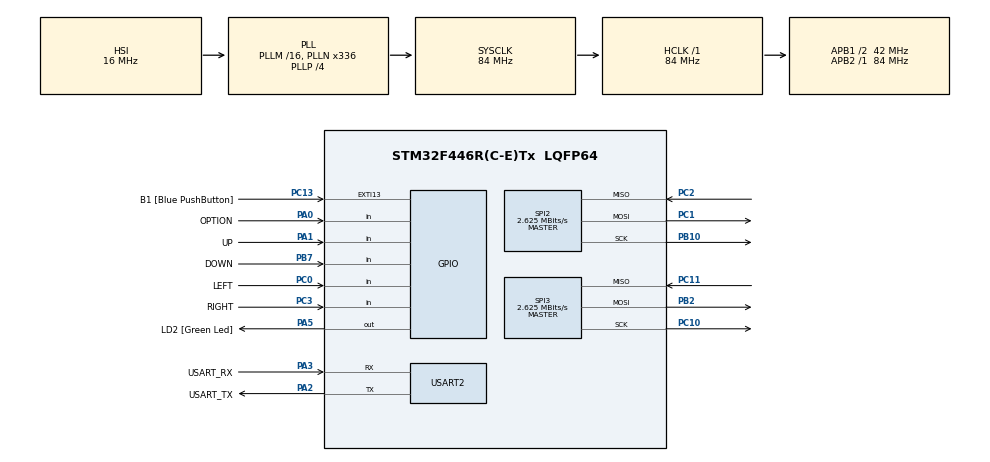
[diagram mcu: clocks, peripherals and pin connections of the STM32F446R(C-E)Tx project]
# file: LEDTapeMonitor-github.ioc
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Dma.Request0=SPI3_TX
Dma.Request1=SPI2_TX
Dma.SPI2_TX.1.Direction=DMA_MEMORY_TO_PERIPH
Dma.SPI2_TX.1.FIFOMode=DMA_FIFOMODE_DISABLE
Dma.SPI2_TX.1.Instance=DMA1_Stream4
Dma.SPI2_TX.1.MemDataAlignment=DMA_MDATAALIGN_BYTE
Dma.SPI2_TX.1.MemInc=DMA_MINC_ENABLE
Dma.SPI2_TX.1.Mode=DMA_NORMAL
Dma.SPI2_TX.1.PeriphDataAlignment=DMA_PDATAALIGN_BYTE
Dma.SPI2_TX.1.PeriphInc=DMA_PINC_DISABLE
Dma.SPI2_TX.1.Priority=DMA_PRIORITY_LOW
Dma.SPI3_TX.0.Direction=DMA_MEMORY_TO_PERIPH
Dma.SPI3_TX.0.FIFOMode=DMA_FIFOMODE_DISABLE
Dma.SPI3_TX.0.Instance=DMA1_Stream5
Dma.SPI3_TX.0.MemDataAlignment=DMA_MDATAALIGN_BYTE
Dma.SPI3_TX.0.MemInc=DMA_MINC_ENABLE
Dma.SPI3_TX.0.Mode=DMA_NORMAL
Dma.SPI3_TX.0.PeriphDataAlignment=DMA_PDATAALIGN_BYTE
Dma.SPI3_TX.0.PeriphInc=DMA_PINC_DISABLE
Dma.SPI3_TX.0.Priority=DMA_PRIORITY_LOW
Mcu.Family=STM32F4
Mcu.Name=STM32F446R(C-E)Tx
Mcu.Package=LQFP64
NVIC.DMA1_Stream4_IRQn=true\:0\:0\:false\:false\:true\:false\:true
NVIC.DMA1_Stream5_IRQn=true\:0\:0\:false\:false\:true\:false\:true
NVIC.PriorityGroup=NVIC_PRIORITYGROUP_0
PA0-WKUP.GPIO_Label=OPTION
PA0-WKUP.GPIO_PuPd=GPIO_PULLDOWN
PA0-WKUP.Signal=GPIO_Input
PA1.GPIO_Label=UP
PA1.GPIO_PuPd=GPIO_NOPULL
PA1.Signal=GPIO_Input
PA13.GPIO_Label=TMS
PA13.Mode=Serial_Wire
PA13.Signal=SYS_JTMS-SWDIO
PA14.GPIO_Label=TCK
PA14.Mode=Serial_Wire
PA14.Signal=SYS_JTCK-SWCLK
PA2.GPIO_Label=USART_TX
PA2.Mode=Asynchronous
PA2.Signal=USART2_TX
PA3.GPIO_Label=USART_RX
PA3.Mode=Asynchronous
PA3.Signal=USART2_RX
PA5.GPIO_Label=LD2 [Green Led]
PA5.Signal=GPIO_Output
PB10.Mode=Full_Duplex_Master
PB10.Signal=SPI2_SCK
PB2.Mode=Full_Duplex_Master
PB2.Signal=SPI3_MOSI
PB3.GPIO_Label=SWO
PB3.Signal=SYS_JTDO-SWO
PB7.GPIO_Label=DOWN
PB7.GPIO_PuPd=GPIO_NOPULL
PB7.Signal=GPIO_Input
PC0.GPIO_Label=LEFT
PC0.GPIO_PuPd=GPIO_NOPULL
PC0.Signal=GPIO_Input
PC1.GPIO_PuPd=GPIO_PULLDOWN
PC1.Mode=Full_Duplex_Master
PC1.Signal=SPI2_MOSI
PC10.Mode=Full_Duplex_Master
PC10.Signal=SPI3_SCK
PC11.Mode=Full_Duplex_Master
PC11.Signal=SPI3_MISO
PC13.GPIO_Label=B1 [Blue PushButton]
PC13.GPIO_ModeDefaultEXTI=GPIO_MODE_IT_FALLING
PC13.Signal=GPXTI13
PC14-OSC32_IN.Mode=LSE-External-Oscillator
PC14-OSC32_IN.Signal=RCC_OSC32_IN
PC15-OSC32_OUT.Mode=LSE-External-Oscillator
PC15-OSC32_OUT.Signal=RCC_OSC32_OUT
PC2.Mode=Full_Duplex_Master
PC2.Signal=SPI2_MISO
PC3.GPIO_Label=RIGHT
PC3.GPIO_PuPd=GPIO_NOPULL
PC3.Signal=GPIO_Input
PH0-OSC_IN.Mode=HSE-External-Oscillator
PH0-OSC_IN.Signal=RCC_OSC_IN
PH1-OSC_OUT.Mode=HSE-External-Oscillator
PH1-OSC_OUT.Signal=RCC_OSC_OUT
ProjectManager.HeapSize=0x200
ProjectManager.StackSize=0x400
ProjectManager.TargetToolchain=STM32CubeIDE
RCC.48MHZClocksFreq_Value=84000000
RCC.AHBFreq_Value=84000000
RCC.APB1CLKDivider=RCC_HCLK_DIV2
RCC.APB1Freq_Value=42000000
RCC.APB1TimFreq_Value=84000000
RCC.APB2Freq_Value=84000000
RCC.APB2TimFreq_Value=84000000
RCC.CortexFreq_Value=84000000
RCC.FLatency-AdvancedSettings=FLASH_LATENCY_2
RCC.HCLKFreq_Value=84000000
RCC.HSE_VALUE=8000000
RCC.HSI_VALUE=16000000
RCC.PLLN=336
RCC.PLLP=RCC_PLLP_DIV4
RCC.SYSCLKFreq_VALUE=84000000
RCC.SYSCLKSource=RCC_SYSCLKSOURCE_PLLCLK
RCC.USBFreq_Value=168000000
RCC.VCOOutputFreq_Value=336000000
SPI2.BaudRatePrescaler=SPI_BAUDRATEPRESCALER_16
SPI2.CLKPhase=SPI_PHASE_2EDGE
SPI2.CalculateBaudRate=2.625 MBits/s
SPI2.Direction=SPI_DIRECTION_2LINES
SPI2.Mode=SPI_MODE_MASTER
SPI2.VirtualType=VM_MASTER
SPI3.BaudRatePrescaler=SPI_BAUDRATEPRESCALER_16
SPI3.CLKPhase=SPI_PHASE_2EDGE
SPI3.CalculateBaudRate=2.625 MBits/s
SPI3.Direction=SPI_DIRECTION_2LINES
SPI3.Mode=SPI_MODE_MASTER
SPI3.VirtualType=VM_MASTER
TIM6.Period=999
TIM6.Prescaler=8399
USART2.VirtualMode=VM_ASYNC
VP_TIM6_VS_ClockSourceINT.Mode=Enable_Timer
board=NUCLEO-F446RE

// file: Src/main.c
/* USER CODE BEGIN Header */
/**
  ******************************************************************************
  * @file           : main.c
  * @brief          : Main program body
  ******************************************************************************
  * @attention
  *
  * <h2><center>&copy; Copyright (c) 2019 STMicroelectronics.
  * All rights reserved.</center></h2>
  *
  * This software component is licensed by ST under BSD 3-Clause license,
  * the "License"; You may not use this file except in compliance with the
  * License. You may obtain a copy of the License at:
  *                        opensource.org/licenses/BSD-3-Clause
  *
  ******************************************************************************
  */
/* USER CODE END Header */

#include "main.h"

/* USER CODE BEGIN Includes */
uint8_t monitor[20][10] = {};//6bit目から2bitずつR G B
uint8_t spi_data[2400] = {};
#include "controlLed.h"
#include "tetris.h"
/* USER CODE END Includes */

SPI_HandleTypeDef hspi2;
SPI_HandleTypeDef hspi3;
DMA_HandleTypeDef hdma_spi2_tx;
DMA_HandleTypeDef hdma_spi3_tx;

TIM_HandleTypeDef htim6;

UART_HandleTypeDef huart2;

void SystemClock_Config(void);
static void MX_GPIO_Init(void);
static void MX_DMA_Init(void);
static void MX_SPI3_Init(void);
static void MX_USART2_UART_Init(void);
static void MX_TIM6_Init(void);
static void MX_SPI2_Init(void);

int main(void)
{

  /* MCU Configuration--------------------------------------------------------*/

  /* Reset of all peripherals, Initializes the Flash interface and the Systick. */
  HAL_Init();

  /* Configure the system clock */
  SystemClock_Config();

  /* Initialize all configured peripherals */
  MX_GPIO_Init();
  MX_DMA_Init();
  MX_SPI3_Init();
  MX_USART2_UART_Init();
  MX_TIM6_Init();
  MX_SPI2_Init();

  /* Infinite loop */
  while (1)
  {

    /* USER CODE BEGIN 3 */

	  playTetris();
	  writeLED();
	  HAL_SPI_Transmit_DMA(&hspi2, spi_data, 2400);
	  //HAL_Delay(1000);
	  //HAL_GPIO_WritePin(GPIOC,GPIO_PIN_1,0);
	  //HAL_Delay(1000);
	 // HAL_GPIO_WritePin(GPIOC,GPIO_PIN_1,1);

  }
  /* USER CODE END 3 */
}

void SystemClock_Config(void)
{
  RCC_OscInitTypeDef RCC_OscInitStruct = {0};
  RCC_ClkInitTypeDef RCC_ClkInitStruct = {0};

  /** Configure the main internal regulator output voltage
  */
  __HAL_RCC_PWR_CLK_ENABLE();
  __HAL_PWR_VOLTAGESCALING_CONFIG(PWR_REGULATOR_VOLTAGE_SCALE3);
  /** Initializes the CPU, AHB and APB busses clocks
  */
  RCC_OscInitStruct.OscillatorType = RCC_OSCILLATORTYPE_HSI;
  RCC_OscInitStruct.HSIState = RCC_HSI_ON;
  RCC_OscInitStruct.HSICalibrationValue = RCC_HSICALIBRATION_DEFAULT;
  RCC_OscInitStruct.PLL.PLLState = RCC_PLL_ON;
  RCC_OscInitStruct.PLL.PLLSource = RCC_PLLSOURCE_HSI;
  RCC_OscInitStruct.PLL.PLLM = 16;
  RCC_OscInitStruct.PLL.PLLN = 336;
  RCC_OscInitStruct.PLL.PLLP = RCC_PLLP_DIV4;
  RCC_OscInitStruct.PLL.PLLQ = 2;
  RCC_OscInitStruct.PLL.PLLR = 2;
  if (HAL_RCC_OscConfig(&RCC_OscInitStruct) != HAL_OK)
  {
    Error_Handler();
  }
  /** Initializes the CPU, AHB and APB busses clocks
  */
  RCC_ClkInitStruct.ClockType = RCC_CLOCKTYPE_HCLK|RCC_CLOCKTYPE_SYSCLK
                              |RCC_CLOCKTYPE_PCLK1|RCC_CLOCKTYPE_PCLK2;
  RCC_ClkInitStruct.SYSCLKSource = RCC_SYSCLKSOURCE_PLLCLK;
  RCC_ClkInitStruct.AHBCLKDivider = RCC_SYSCLK_DIV1;
  RCC_ClkInitStruct.APB1CLKDivider = RCC_HCLK_DIV2;
  RCC_ClkInitStruct.APB2CLKDivider = RCC_HCLK_DIV1;

  if (HAL_RCC_ClockConfig(&RCC_ClkInitStruct, FLASH_LATENCY_2) != HAL_OK)
  {
    Error_Handler();
  }
}

static void MX_SPI2_Init(void)
{

  /* SPI2 parameter configuration*/
  hspi2.Instance = SPI2;
  hspi2.Init.Mode = SPI_MODE_MASTER;
  hspi2.Init.Direction = SPI_DIRECTION_2LINES;
  hspi2.Init.DataSize = SPI_DATASIZE_8BIT;
  hspi2.Init.CLKPolarity = SPI_POLARITY_LOW;
  hspi2.Init.CLKPhase = SPI_PHASE_2EDGE;
  hspi2.Init.NSS = SPI_NSS_SOFT;
  hspi2.Init.BaudRatePrescaler = SPI_BAUDRATEPRESCALER_16;
  hspi2.Init.FirstBit = SPI_FIRSTBIT_MSB;
  hspi2.Init.TIMode = SPI_TIMODE_DISABLE;
  hspi2.Init.CRCCalculation = SPI_CRCCALCULATION_DISABLE;
  hspi2.Init.CRCPolynomial = 10;
  if (HAL_SPI_Init(&hspi2) != HAL_OK)
  {
    Error_Handler();
  }

}

static void MX_SPI3_Init(void)
{

  /* SPI3 parameter configuration*/
  hspi3.Instance = SPI3;
  hspi3.Init.Mode = SPI_MODE_MASTER;
  hspi3.Init.Direction = SPI_DIRECTION_2LINES;
  hspi3.Init.DataSize = SPI_DATASIZE_8BIT;
  hspi3.Init.CLKPolarity = SPI_POLARITY_LOW;
  hspi3.Init.CLKPhase = SPI_PHASE_2EDGE;
  hspi3.Init.NSS = SPI_NSS_SOFT;
  hspi3.Init.BaudRatePrescaler = SPI_BAUDRATEPRESCALER_16;
  hspi3.Init.FirstBit = SPI_FIRSTBIT_MSB;
  hspi3.Init.TIMode = SPI_TIMODE_DISABLE;
  hspi3.Init.CRCCalculation = SPI_CRCCALCULATION_DISABLE;
  hspi3.Init.CRCPolynomial = 10;
  if (HAL_SPI_Init(&hspi3) != HAL_OK)
  {
    Error_Handler();
  }

}

static void MX_TIM6_Init(void)
{

  TIM_MasterConfigTypeDef sMasterConfig = {0};

  htim6.Instance = TIM6;
  htim6.Init.Prescaler = 8399;
  htim6.Init.CounterMode = TIM_COUNTERMODE_UP;
  htim6.Init.Period = 999;
  htim6.Init.AutoReloadPreload = TIM_AUTORELOAD_PRELOAD_DISABLE;
  if (HAL_TIM_Base_Init(&htim6) != HAL_OK)
  {
    Error_Handler();
  }
  sMasterConfig.MasterOutputTrigger = TIM_TRGO_RESET;
  sMasterConfig.MasterSlaveMode = TIM_MASTERSLAVEMODE_DISABLE;
  if (HAL_TIMEx_MasterConfigSynchronization(&htim6, &sMasterConfig) != HAL_OK)
  {
    Error_Handler();
  }

}

static void MX_USART2_UART_Init(void)
{

  huart2.Instance = USART2;
  huart2.Init.BaudRate = 115200;
  huart2.Init.WordLength = UART_WORDLENGTH_8B;
  huart2.Init.StopBits = UART_STOPBITS_1;
  huart2.Init.Parity = UART_PARITY_NONE;
  huart2.Init.Mode = UART_MODE_TX_RX;
  huart2.Init.HwFlowCtl = UART_HWCONTROL_NONE;
  huart2.Init.OverSampling = UART_OVERSAMPLING_16;
  if (HAL_UART_Init(&huart2) != HAL_OK)
  {
    Error_Handler();
  }

}

static void MX_DMA_Init(void)
{

  /* DMA controller clock enable */
  __HAL_RCC_DMA1_CLK_ENABLE();

  /* DMA interrupt init */
  /* DMA1_Stream4_IRQn interrupt configuration */
  HAL_NVIC_SetPriority(DMA1_Stream4_IRQn, 0, 0);
  HAL_NVIC_EnableIRQ(DMA1_Stream4_IRQn);
  /* DMA1_Stream5_IRQn interrupt configuration */
  HAL_NVIC_SetPriority(DMA1_Stream5_IRQn, 0, 0);
  HAL_NVIC_EnableIRQ(DMA1_Stream5_IRQn);

}

static void MX_GPIO_Init(void)
{
  GPIO_InitTypeDef GPIO_InitStruct = {0};

  /* GPIO Ports Clock Enable */
  __HAL_RCC_GPIOC_CLK_ENABLE();
  __HAL_RCC_GPIOH_CLK_ENABLE();
  __HAL_RCC_GPIOA_CLK_ENABLE();
  __HAL_RCC_GPIOB_CLK_ENABLE();

  /*Configure GPIO pin Output Level */
  HAL_GPIO_WritePin(LD2_GPIO_Port, LD2_Pin, GPIO_PIN_RESET);

  /*Configure GPIO pin : B1_Pin */
  GPIO_InitStruct.Pin = B1_Pin;
  GPIO_InitStruct.Mode = GPIO_MODE_IT_FALLING;
  GPIO_InitStruct.Pull = GPIO_NOPULL;
  HAL_GPIO_Init(B1_GPIO_Port, &GPIO_InitStruct);

  /*Configure GPIO pins : LEFT_Pin RIGHT_Pin */
  GPIO_InitStruct.Pin = LEFT_Pin|RIGHT_Pin;
  GPIO_InitStruct.Mode = GPIO_MODE_INPUT;
  GPIO_InitStruct.Pull = GPIO_NOPULL;
  HAL_GPIO_Init(GPIOC, &GPIO_InitStruct);

  /*Configure GPIO pin : OPTION_Pin */
  GPIO_InitStruct.Pin = OPTION_Pin;
  GPIO_InitStruct.Mode = GPIO_MODE_INPUT;
  GPIO_InitStruct.Pull = GPIO_PULLDOWN;
  HAL_GPIO_Init(OPTION_GPIO_Port, &GPIO_InitStruct);

  /*Configure GPIO pin : UP_Pin */
  GPIO_InitStruct.Pin = UP_Pin;
  GPIO_InitStruct.Mode = GPIO_MODE_INPUT;
  GPIO_InitStruct.Pull = GPIO_NOPULL;
  HAL_GPIO_Init(UP_GPIO_Port, &GPIO_InitStruct);

  /*Configure GPIO pin : LD2_Pin */
  GPIO_InitStruct.Pin = LD2_Pin;
  GPIO_InitStruct.Mode = GPIO_MODE_OUTPUT_PP;
  GPIO_InitStruct.Pull = GPIO_NOPULL;
  GPIO_InitStruct.Speed = GPIO_SPEED_FREQ_LOW;
  HAL_GPIO_Init(LD2_GPIO_Port, &GPIO_InitStruct);

  /*Configure GPIO pin : DOWN_Pin */
  GPIO_InitStruct.Pin = DOWN_Pin;
  GPIO_InitStruct.Mode = GPIO_MODE_INPUT;
  GPIO_InitStruct.Pull = GPIO_NOPULL;
  HAL_GPIO_Init(DOWN_GPIO_Port, &GPIO_InitStruct);

}

void Error_Handler(void)
{
}

/************************ (C) COPYRIGHT STMicroelectronics *****END OF FILE****/
